# CY8C4246AZI_L445 register map
File version: 0.1
PSoC 4200L
Registers are 32-bit, read-write, no defined reset value unless marked. A register's access mark holds for its fields unless they carry their own. Offsets are from the block's base; lines under a group give offsets from that group; [hi:lo] are bit positions; {n}, {i} and the like mark numbered series; 'fields as' and 'values as' point back to an identical list; <NAME> marks a mode.

## Memory map
0x00000000 Opamp
0x00000000 MIDI1_UART — UART
0x00000000 USB — USBFS
0x00000000 DMAC — DMAC Registers
0x00000000 IDAC_1 — IDAC
0x00000000 main_osc_PWM_3
0x00000000 ADC_SAR_Seq — Sequencing SAR ADC
0x00000000 main_osc_PWM_0
0x00000000 envelope_PWM_0
0x00000000 CapSense_Buttons_IDAC1 — IDAC
0x00000000 CapSense_Buttons_IDAC2 — IDAC
0x00000000 envelope_PWM_1
0x00000000 envelope_PWM_3
0x00000000 envelope_PWM_2
0x00000000 main_osc_PWM_1
0x00000000 main_osc_PWM_2

## Opamp
Base 0x00000000
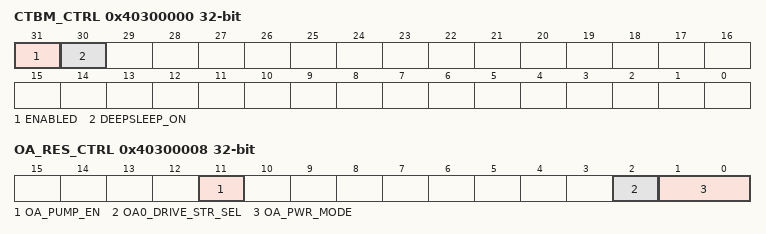
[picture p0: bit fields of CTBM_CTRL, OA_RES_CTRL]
0x40300000 CTBM_CTRL — Global CTB IP and power control
  [31] ENABLED — Selects component behavior in DeepSleep power mode
    0=DISABLE (CTB IP disabled (put analog in power down, open all switches)); 1=ENABLE (CTB IP enabledCTB IP enabled)
  [30] DEEPSLEEP_ON — Selects component behavior in DeepSleep power mode
    0=DISABLE (CTB IP disabled off during DeepSleep power mode); 1=ENABLE (CTB IP remains enabled during DeepSleep power mode (if ENABLED=1))
0x40300008 OA_RES_CTRL — Opamp and resistor control
  [11] OA_PUMP_EN — Selects pump
    0=DISABLE (Pump disabled); 1=ENABLE (Pump enabled)
  [2] OA0_DRIVE_STR_SEL — Opamp output strenght select
    0=Cy1x (Internal only); 1=Cy10x (Output to pin)
  [1:0] OA_PWR_MODE — Selects power for opamp
    0=OFF; 1=LOW (Low power); 2=MED (Medium power); 3=HIGH (High power)
0x40300F14 OA_COMP_TRIM — Opamp Compenation Capacitor Trim
  [1:0] OA_COMP_TRIM
    1=HIGH_SPEED; 2=BALANCED; 3=HIGH_STABILITY

## MIDI1_UART — UART
Base 0x00000000
0x400F0021 RX_MIDI1_UART_RX_ADDRESS1 8-bit — RX Address1 Register
0x400F0031 RX_MIDI1_UART_RX_ADDRESS2 8-bit — RX Address2 Register
0x400F0041 RX_MIDI1_UART_RX_DATA 8-bit — RX Data Register
0x400F0043 TX_MIDI1_UART_TX_DATA 8-bit — TX Data Register
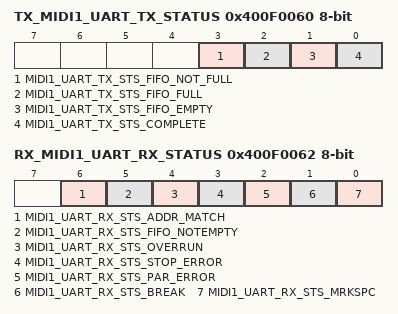
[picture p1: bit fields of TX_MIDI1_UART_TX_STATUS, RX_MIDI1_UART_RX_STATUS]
0x400F0060 TX_MIDI1_UART_TX_STATUS 8-bit — TX status register
  [3] MIDI1_UART_TX_STS_FIFO_NOT_FULL ro, [2] MIDI1_UART_TX_STS_FIFO_FULL ro, [1] MIDI1_UART_TX_STS_FIFO_EMPTY ro, [0] MIDI1_UART_TX_STS_COMPLETE ro
0x400F0062 RX_MIDI1_UART_RX_STATUS 8-bit — RX status register
  [6] MIDI1_UART_RX_STS_ADDR_MATCH ro, [5] MIDI1_UART_RX_STS_FIFO_NOTEMPTY ro, [4] MIDI1_UART_RX_STS_OVERRUN ro, [3] MIDI1_UART_RX_STS_STOP_ERROR ro, [2] MIDI1_UART_RX_STS_PAR_ERROR ro, [1] MIDI1_UART_RX_STS_BREAK ro, [0] MIDI1_UART_RX_STS_MRKSPC ro

## IDAC_1 — IDAC
Base 0x00000000
0x40290004 CSD_IDAC_POLARITY
0x40290008 CSD_IDAC
0x4029FF00 CSD_TRIM1 — CSD IDAC TRIM1
0x4029FF04 CSD_TRIM2 — CSD IDAC TRIM2

## main_osc_PWM_3
Base 0x00000000
0x40200288 COUNTER — Current counter value
0x4020028C CC — Compare / capture value
0x40200290 CC_BUF — Compare / capture buffer value
0x40200294 PERIOD — Period value
0x40200298 PERIOD_BUF — Period buffer value

## main_osc_PWM_0
Base 0x00000000
0x402001C8 COUNTER — Current counter value
0x402001CC CC — Compare / capture value
0x402001D0 CC_BUF — Compare / capture buffer value
0x402001D4 PERIOD — Period value
0x402001D8 PERIOD_BUF — Period buffer value

## envelope_PWM_0
Base 0x00000000
0x40200208 COUNTER — Current counter value
0x4020020C CC — Compare / capture value
0x40200210 CC_BUF — Compare / capture buffer value
0x40200214 PERIOD — Period value
0x40200218 PERIOD_BUF — Period buffer value

## CapSense_Buttons_IDAC1 — IDAC
Base 0x00000000
Same registers: CapSense_Buttons_IDAC2 0x00000000
0x40280004 CSD_IDAC_POLARITY
0x40280008 CSD_IDAC
0x4028FF00 CSD_TRIM1 — CSD IDAC TRIM1
0x4028FF04 CSD_TRIM2 — CSD IDAC TRIM2

## envelope_PWM_1
Base 0x00000000
0x40200108 COUNTER — Current counter value
0x4020010C CC — Compare / capture value
0x40200110 CC_BUF — Compare / capture buffer value
0x40200114 PERIOD — Period value
0x40200118 PERIOD_BUF — Period buffer value
